# PY32F002Bxx register map
Vendor: Puya; Series: PY32F0; File version: 1.0.0
CPU: CM0+ r0p1, little endian, no MPU, no FPU, 4 interrupt priority bits
Registers are 32-bit, read-write, reset 0x0 unless marked. A register's access mark holds for its fields unless they carry their own. Offsets are from the block's base; [hi:lo] are bit positions; {n}, {i} and the like mark numbered series; 'fields as' and 'values as' point back to an identical list.

## PWR — Power control
Base 0x40007000
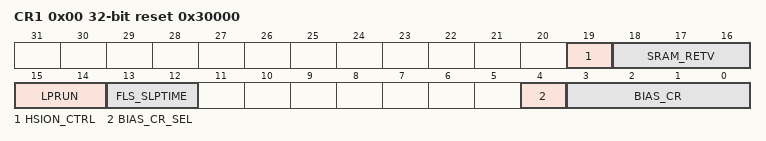
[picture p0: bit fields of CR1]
0x00 CR1 reset 0x30000 — Power control register 1
  [19] HSION_CTRL — HSI open time control
    0=WaiteMR (Enable HSI after MR is stable); 1=WakeOnVR (Enable HSI when VR is on (enable HSI immediately when wakeup))
  [18:16] SRAM_RETV — SRAM retention voltage control
    3=V0_9 (Supply voltage 0.9 V for SRAM); 4=V1_x (Supply voltage 1.0 or 1.2 V (depends on VOS) for SRAM)
  [15:14] LPRUN — Low-power run
    0=MainMode (Voltage regulator in Main mode in Low-power run mode); 1=LowPowerMode (Voltage regulator in low-power mode in Low-power run mode)
  [13:12] FLS_SLPTIME — Flash wait time after wakeup from the stop mode
    0=FiveMicroSec (Flash wait 5 us after wakeup from stop mode); 1=TwoMicroSec (Flash wait 2 us after wakeup from stop mode); 2=ThreeMicroSec (Flash wait 3 us after wakeup from stop mode); 3=ExcuteFromSRAM (Excute program from SRAM after wakeup from stop mode)
  [4] BIAS_CR_SEL — MR Bias current selection
    0=FactoryConfig (Bias config from factory config bytes); 1=BiasCR (Bias config from BIAS_CR register)
  [3:0] BIAS_CR — MR Bias current

## GPIOA — General-purpose I/Os
Base 0x50000000
Same registers: GPIOB 0x50000400
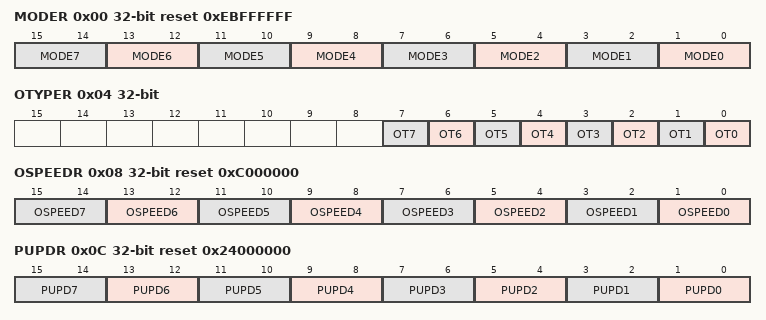
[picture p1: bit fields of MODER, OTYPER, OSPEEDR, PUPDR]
0x00 MODER reset 0xEBFFFFFF — GPIO port mode register
  [all] fields
    0=Input mode; 1=Output (General purpose output mode); 2=Alternate function mode; 3=Analog mode
  [2n+1:2n] MODE{n} (n=0..7) — Port x configuration bits (y = 0..15)
0x04 OTYPER — GPIO port output type register
  [all] fields
    0=PushPull (Output push-pull (reset state)); 1=OpenDrain (Output open-drain)
  [n] OT{n} (n=0..7) — Port x configuration bits (y = 0..15)
0x08 OSPEEDR reset 0xC000000 — GPIO port output speed register
  [all] fields
    0=LowSpeed; 1=MediumSpeed; 2=HighSpeed; 3=VeryHighSpeed
  [2n+1:2n] OSPEED{n} (n=0..7) — Port x configuration bits (y = 0..15)
0x0C PUPDR reset 0x24000000 — GPIO port pull-up/pull-down register
  [all] fields
    0=Floating (No pull-up, pull-down); 1=PullUp; 2=PullDown
  [2n+1:2n] PUPD{n} (n=0..7) — Port x configuration bits (y = 0..15)
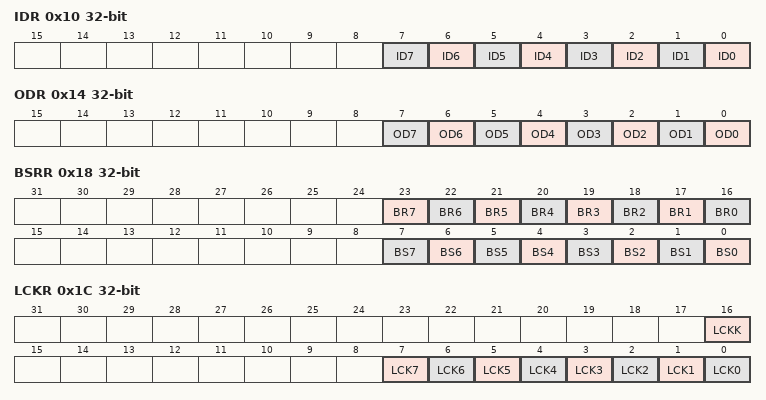
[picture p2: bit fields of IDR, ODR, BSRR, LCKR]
0x10 IDR ro — GPIO port input data register
  [all] fields
    0=Low (Input is logic low); 1=High (Input is logic high)
  [n] ID{n} (n=0..7) — Port input data (y = 0..15)
0x14 ODR — GPIO port output data register
  [all] fields
    0=Low (Set output to logic low); 1=High (Set output to logic high)
  [n] OD{n} (n=0..7) — Port output data (y = 0..15)
0x18 BSRR wo — GPIO port bit set/reset register
  [n+16] BR{n} (n=1..7) — Port x reset bit y (y = 0..15)
    1=Resets the corresponding ODx bit
  [16] BR0 — Port x set bit y (y= 0..15)
    1=Resets the corresponding ODx bit
  [n] BS{n} (n=0..7) — Port x set bit y (y= 0..15)
    1=Set (Sets the corresponding ODx bit)
0x1C LCKR — GPIO port configuration lock register
  [16] LCKK — Port x lock bit y (y= 0..15)
    0=NotActive (Port configuration lock key not active); 1=Active (Port configuration lock key active)
  [n] LCK{n} (n=0..7) — Port x lock bit y (y= 0..15)
    0=Unlocked (Port configuration not locked); 1=Locked (Port configuration locked)
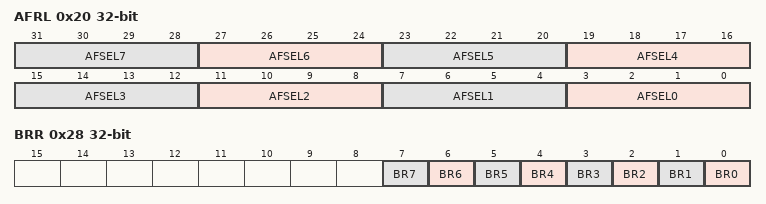
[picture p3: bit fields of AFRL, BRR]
0x20 AFRL — GPIO alternate function low register
  [all] fields
    {v}=AF{v} (v=0..15)
  [4n+3:4n] AFSEL{n} (n=0..7) — Alternate function selection for port x bit y (y = 0..7)
0x28 BRR wo — port bit reset register
  [all] fields
    0=No action on the corresponding ODx bit; 1=Reset the ODx bit
  [n] BR{n} (n=0..7) — Port Reset bit

## GPIOC — General-purpose I/Os
Base 0x50000800
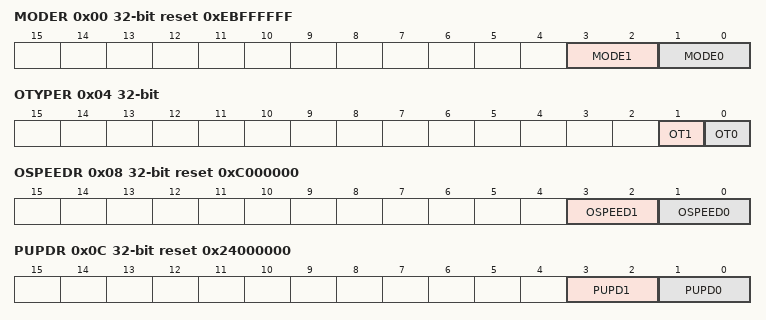
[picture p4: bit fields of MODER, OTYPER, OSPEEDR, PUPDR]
0x00 MODER reset 0xEBFFFFFF — GPIO port mode register
  [3:2] MODE1 — Port x configuration bits (y = 0..15)
    0=Input mode; 1=Output (General purpose output mode); 2=Alternate function mode; 3=Analog mode
  [1:0] MODE0 — Port x configuration bits (y = 0..15)
    values as MODE1
0x04 OTYPER — GPIO port output type register
  [1] OT1 — Port x configuration bits (y = 0..15)
    0=PushPull (Output push-pull (reset state)); 1=OpenDrain (Output open-drain)
  [0] OT0 — Port x configuration bits (y = 0..15)
    values as OT1
0x08 OSPEEDR reset 0xC000000 — GPIO port output speed register
  [3:2] OSPEED1 — Port x configuration bits (y = 0..15)
    0=LowSpeed; 1=MediumSpeed; 2=HighSpeed; 3=VeryHighSpeed
  [1:0] OSPEED0 — Port x configuration bits (y = 0..15)
    0=LowSpeed; 1=MediumSpeed; 2=HighSpeed; 3=VeryHighSpeed
0x0C PUPDR reset 0x24000000 — GPIO port pull-up/pull-down register
  [3:2] PUPD1 — Port x configuration bits (y = 0..15)
    0=Floating (No pull-up, pull-down); 1=PullUp; 2=PullDown
  [1:0] PUPD0 — Port x configuration bits (y = 0..15)
    0=Floating (No pull-up, pull-down); 1=PullUp; 2=PullDown
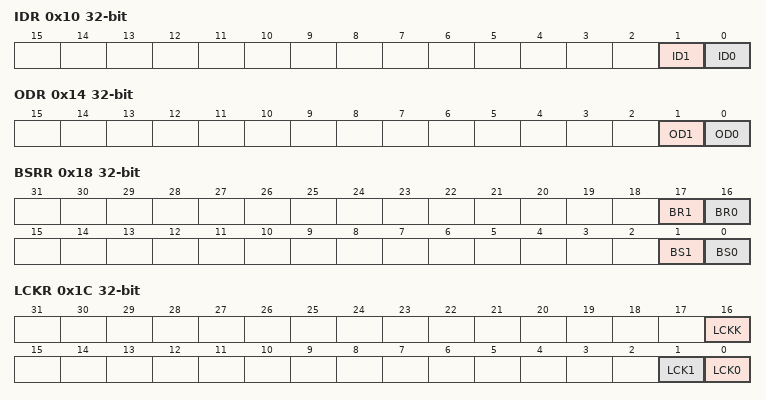
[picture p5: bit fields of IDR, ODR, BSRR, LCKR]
0x10 IDR ro — GPIO port input data register
  [1] ID1 — Port input data (y = 0..15)
    0=Low (Input is logic low); 1=High (Input is logic high)
  [0] ID0 — Port input data (y = 0..15)
    0=Low (Input is logic low); 1=High (Input is logic high)
0x14 ODR — GPIO port output data register
  [1] OD1 — Port output data (y = 0..15)
    0=Low (Set output to logic low); 1=High (Set output to logic high)
  [0] OD0 — Port output data (y = 0..15)
    values as OD1
0x18 BSRR wo — GPIO port bit set/reset register
  [17] BR1 — Port x reset bit y (y = 0..15)
    1=Resets the corresponding ODx bit
  [16] BR0 — Port x set bit y (y= 0..15)
    1=Resets the corresponding ODx bit
  [1] BS1 — Port x set bit y (y= 0..15)
    1=Set (Sets the corresponding ODx bit)
  [0] BS0 — Port x set bit y (y= 0..15)
    1=Set (Sets the corresponding ODx bit)
0x1C LCKR — GPIO port configuration lock register
  [16] LCKK — Port x lock bit y (y= 0..15)
    0=NotActive (Port configuration lock key not active); 1=Active (Port configuration lock key active)
  [1] LCK1 — Port x lock bit y (y= 0..15)
    0=Unlocked (Port configuration not locked); 1=Locked (Port configuration locked)
  [0] LCK0 — Port x lock bit y (y= 0..15)
    values as LCK1
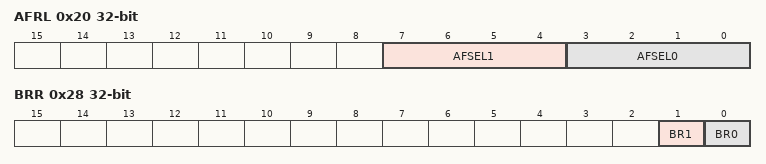
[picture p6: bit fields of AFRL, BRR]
0x20 AFRL — GPIO alternate function low register
  [7:4] AFSEL1 — Alternate function selection for port x bit y (y = 0..7)
    {v}=AF{v} (v=0..15)
  [3:0] AFSEL0 — Alternate function selection for port x bit y (y = 0..7)
    {v}=AF{v} (v=0..15)
0x28 BRR wo — port bit reset register
  [1] BR1 — Port Reset bit
    0=No action on the corresponding ODx bit; 1=Reset the ODx bit
  [0] BR0 — Port Reset bit
    values as BR1
